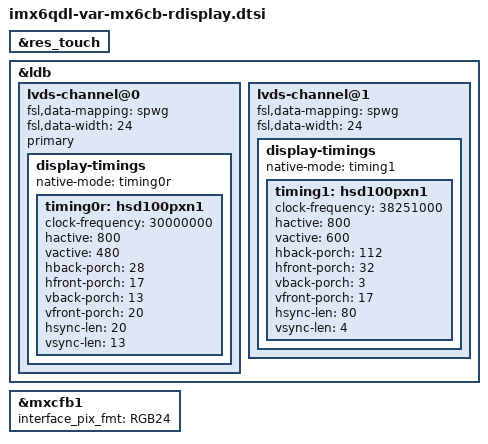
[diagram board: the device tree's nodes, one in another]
/*
 * Copyright (C) 2015-2017 Variscite Ltd.
 *
 * This program is free software; you can redistribute it and/or modify
 * it under the terms of the GNU General Public License version 2 as
 * published by the Free Software Foundation.
 *
 * Resistive Display for VAR-MX6CustomBoard
 */

&res_touch {
	status = "okay";
};

&ldb {
	status = "okay";

	lvds-channel@0 {
		fsl,data-mapping = "spwg";
		fsl,data-width = <24>;
		status = "okay";
		primary;

		display-timings {
			native-mode = <&timing0r>;
			timing0r: hsd100pxn1 {
				clock-frequency = <30000000>;
				hactive = <800>;
				vactive = <480>;
				hback-porch = <28>;
				hfront-porch = <17>;
				vback-porch = <13>;
				vfront-porch = <20>;
				hsync-len = <20>;
				vsync-len = <13>;
			};
		};
	};

	lvds-channel@1 {
		fsl,data-mapping = "spwg";
		fsl,data-width = <24>;
		status = "okay";

		display-timings {
			native-mode = <&timing1>;
			timing1: hsd100pxn1 {
				clock-frequency = <38251000>;
				hactive = <800>;
				vactive = <600>;
				hback-porch = <112>;
				hfront-porch = <32>;
				vback-porch = <3>;
				vfront-porch = <17>;
				hsync-len = <80>;
				vsync-len = <4>;
			};
		};
	};
};

&mxcfb1 {
	interface_pix_fmt = "RGB24";
};
